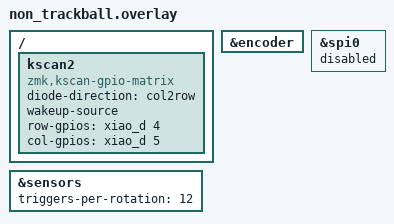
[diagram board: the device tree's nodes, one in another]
/delete-node/ &kscan2;

&encoder {
    status = "okay";
};

&spi0 {
    status = "disabled";
};

/ {
    // 物理ピン
    kscan2: kscan2 {
        compatible = "zmk,kscan-gpio-matrix";
        diode-direction = "col2row";    // カソードが行
        wakeup-source;
        row-gpios
            = <&xiao_d 4 (GPIO_ACTIVE_HIGH | GPIO_PULL_DOWN)>
            ; 

        col-gpios
            = <&xiao_d 5 GPIO_ACTIVE_HIGH>
            ; 
    };
};

&sensors {
    triggers-per-rotation = <12>;
};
